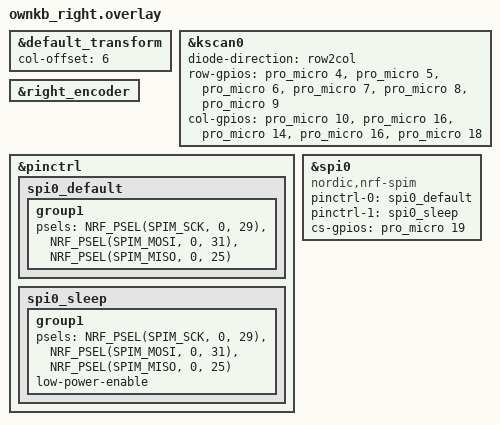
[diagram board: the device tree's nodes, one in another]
/*
 * Copyright (c) 2023 The ZMK Contributors
 * SPDX-License-Identifier: MIT
 */

#include "ownkb.dtsi"

&default_transform {
    col-offset = <6>;
};

&kscan0 {
    diode-direction = "row2col";
    row-gpios
        = <&pro_micro 4 (GPIO_ACTIVE_HIGH)>
        , <&pro_micro 5 (GPIO_ACTIVE_HIGH)>
        , <&pro_micro 6 (GPIO_ACTIVE_HIGH)>
        , <&pro_micro 7 (GPIO_ACTIVE_HIGH)>
        , <&pro_micro 8 (GPIO_ACTIVE_HIGH)>
        , <&pro_micro 9 (GPIO_ACTIVE_HIGH)>
        ;
    col-gpios
        = <&pro_micro 10 (GPIO_ACTIVE_HIGH | GPIO_PULL_DOWN)>
        , <&pro_micro 16 (GPIO_ACTIVE_HIGH | GPIO_PULL_DOWN)>
        , <&pro_micro 14 (GPIO_ACTIVE_HIGH | GPIO_PULL_DOWN)>
        , <&pro_micro 16 (GPIO_ACTIVE_HIGH | GPIO_PULL_DOWN)>
        , <&pro_micro 18 (GPIO_ACTIVE_HIGH | GPIO_PULL_DOWN)>
        ;
};

&right_encoder {
    status = "okay";
};

&pinctrl {
    spi0_default: spi0_default {
        group1 {
            psels = <NRF_PSEL(SPIM_SCK, 0, 29)>,
                <NRF_PSEL(SPIM_MOSI, 0, 31)>,
                <NRF_PSEL(SPIM_MISO, 0, 25)>;
        };
    };
    spi0_sleep: spi0_sleep {
        group1 {
            psels = <NRF_PSEL(SPIM_SCK, 0, 29)>,
                <NRF_PSEL(SPIM_MOSI, 0, 31)>,
                <NRF_PSEL(SPIM_MISO, 0, 25)>;
            low-power-enable;
        };
    };
};

nice_view_spi: &spi0 {
    compatible = "nordic,nrf-spim";
    pinctrl-0 = <&spi0_default>;
    pinctrl-1 = <&spi0_sleep>;
    pinctrl-names = "default", "sleep";
    cs-gpios = <&pro_micro 19 GPIO_ACTIVE_HIGH>;
};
